# pse84 register map
Vendor: Cypress Semiconductor; Series: PSE84; File version: 1.0
CPU: CM33 r0p1, little endian, MPU, FPU, VTOR, 3 interrupt priority bits
Registers are 32-bit, read-write, reset 0x0 unless marked. A register's access mark holds for its fields unless they carry their own. Offsets are from the block's base; [hi:lo] are bit positions; {n}, {i} and the like mark numbered series; <NAME> marks a mode.

## SCB0 (part 1 of 2) — Serial Communications Block (SPI/UART/I2C)
Base 0x42990000
Same registers: SCB{n} {0x42980000+0x10000*n} (n=2..11), SCB1 0x42D00000
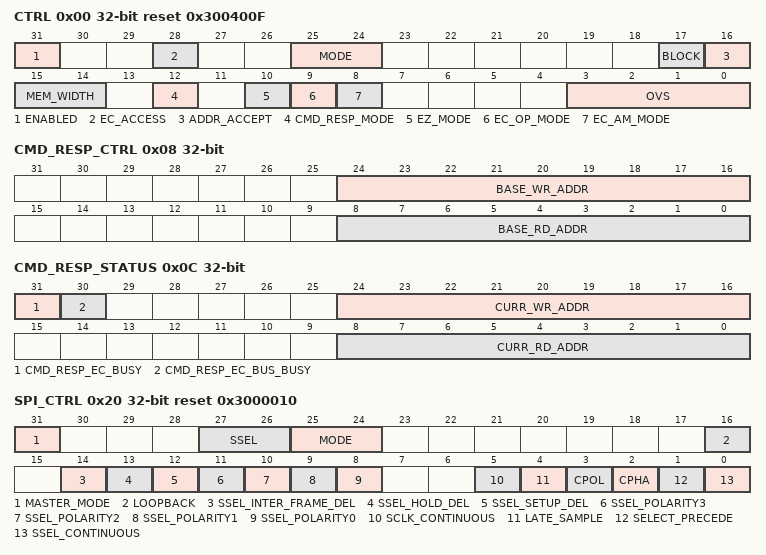
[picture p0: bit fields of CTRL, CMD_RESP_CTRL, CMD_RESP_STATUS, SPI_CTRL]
0x00 CTRL reset 0x300400F — Generic control
  [31] ENABLED — IP enabled ('1') or not ('0'). The proper order in which to initialize the IP is as follows: - Program protocol specific information using SPI_CTRL, UART_CTRL (and UART_TX_CTRL and UART_RX_CTRL) or I2C_CTRL. This includes selection of a submode, master/slave functionality and transmitter/receiver functionality when applicable. - Program generic transmitter (TX_CTRL) and receiver (RX_CTRL) information. This includes enabling of the transmitter and receiver functionality. - Program transmitter FIFO (TX_FIFO_CTRL) and receiver FIFO (RX_FIFO_CTRL) information. - Program CTRL to enable IP, select the specific operation mode and oversampling factor. Generally hen the IP is enabled, no control information should be changed. Changes should be made AFTER disabling the IP, e.g. to modify the operation mode (from I2C to SPI) or to go from externally to internally clocked. The change takes effect after the IP is re-enabled. Note that disabling the IP will cause re-initialization of the design and associated state is lost (e.g. FIFO content). Specific to SPI master case, when SCB is idle, below registers can be changed without disabling SCB block, TX_CTRL TX_FIFO_CTRL RX_CTRL RX_FIFO_CTRL SPI_CTRL.SSEL,
  [28] EC_ACCESS — used to enable I2CS_EC or SPIS_EC access to internal SRAM memory. 0: enable clock_scb_en, has no effect on ec_busy_pp 1: disable clock_scb_en, enable ec_busy_pp (grant I2CS_EC or SPIS_EC access) Before going to deepsleep this field should be set to 1. when waking up from DeepSleep power mode, and PLL is locked (clk_scb is at expected frequency), this filed should be set to 0.
  [25:24] MODE
    0=I2C (Inter-Integrated Circuits (I2C) mode.); 1=SPI (Serial Peripheral Interface (SPI) mode.); 2=UART (Universal Asynchronous Receiver/Transmitter (UART) mode.)
  [17] BLOCK — Only used in externally clocked mode. If the externally clocked logic and the MMIO SW accesses to EZ memory coincide/collide, this bit determines whether a SW access should block and result in bus wait states ('BLOCK is 1') or not (BLOCK is '0'). IF BLOCK is '0' and the accesses collide, MMIO read operations return 0xffff:ffff and MMIO write operations are ignored. Colliding accesses are registered as interrupt causes: field BLOCKED of MMIO registers INTR_TX and INTR_RX.
  [16] ADDR_ACCEPT — Determines whether a received matching address is accepted in the RX FIFO ('1') or not ('0'). In I2C mode, this field is used to allow the slave to put the received slave address or general call address in the RX FIFO. Note that a received matching address is put in the RX FIFO when ADDR_ACCEPT is '1' for both I2C read and write transfers. In multi-processor UART receiver mode, this field is used to allow the receiver to put the received address in the RX FIFO. Note: non-matching addresses are never put in the RX FIFO.
  [15:14] MEM_WIDTH — Determines the number of bits per FIFO data element, depending on physical SRAM cell data width. On M0S8/MXS40S platform, the SRAM data width is 16 bit, so WORD (2) is not supported. On MXS40E platform, the SRAM data width is 32 bits.
    0=BYTE (8-bit FIFO data elements. This mode provides the biggest amount of FIFO entries, but TX_CTRL.DATA_WIDTH and RX_CTRL.DATA_WIDTH are restricted to [0, 7].); 1=HALFWORD (16-bit FIFO data elements. TX_CTRL.DATA_WIDTH and RX_CTRL.DATA_WIDTH are restricted to [0, 15].); 2=WORD (32-bit FIFO data elements. This mode provides the smallest amount of FIFO entries, but TX_CTRL.DATA_WIDTH and RX_CTRL.DATA_WIDTH can be in a range of [0, 31].); 3=RSVD (N/A)
  [12] CMD_RESP_MODE — Determines CMD_RESP mode of operation: '0': CMD_RESP mode disabled. '1': CMD_RESP mode enabled (also requires EC_AM_MODE and EC_OP_MODE to be set to '1').
  [10] EZ_MODE — Non EZ mode ('0') or EZ mode ('1'). In EZ mode, a meta protocol is applied to the serial interface protocol. This meta protocol adds meaning to the data frames transferred by the serial interface protocol: a data frame can represent a memory address, a write memory data element or a read memory data element. EZ mode is only used for synchronous serial interface protocols: SPI and I2C. In SPI mode, only Motorola submode (all Motorola modes: 0, 1, 2, 3) is supported and the transmitter should use continuous data frames; i.e. data frames mot separated by slave deselection. This mode is only applicable to slave functionality. In EZ mode, the slave can read from and write to an addressable memory structure of up to 256 bytes. In EZ mode, data frames should 8-bit in size and should be transmitted and received with the Most Significant Bit (MSB) first. In UART mode this field should be '0'.
  [9] EC_OP_MODE — Internally clocked mode ('0') or externally clocked mode ('1') operation. In internally clocked mode, the serial interface protocols run off the peripheral clock. In externally clocked mode, the serial interface protocols run off the clock as provided by the serial interface. Externally clocked operation mode is only used for synchronous serial interface protocols (SPI and I2C) in slave mode AND EZ mode. In SPI mode, only Motorola submode (all Motorola modes: 0, 1, 2, 3) is supported. The maximum SPI slave, EZ mode bitrate is 48 Mbps (transmission and IO delays outside the IP will degrade the effective bitrate). In UART mode this field should be '0'.
  [8] EC_AM_MODE — Internally clocked mode ('0') or externally clocked mode ('1') address matching (I2C) or selection (SPI). In internally clocked mode, the serial interface protocols run off the peripheral clock. In externally clocked mode, the serial interface protocols run off the clock as provided by the serial interface. Externally clocked mode is only used for synchronous serial interface protocols (SPI and I2C) in slave mode. In SPI mode, only Motorola submode (all Motorola modes: 0, 1, 2, 3) is supported. In UART mode this field should be '0'.
  [3:0] OVS
0x04 STATUS ro reset not defined — Generic status
  [0] EC_BUSY — Indicates whether the externally clocked logic is potentially accessing the EZ memory (this is only possible in EZ mode). This bit can be used by SW to determine whether it is safe to issue a SW access to the EZ memory (without bus wait states (a blocked SW access) or bus errors being generated). Note that the INTR_TX.BLOCKED and INTR_RX.BLOCKED interrupt causes are used to indicate whether a SW access was actually blocked by externally clocked logic.
0x08 CMD_RESP_CTRL — Command/response control
  [24:16] BASE_WR_ADDR — I2C/SPI write base address for CMD_RESP mode. Address is used by a I2C CMD_RESP mode write transfer (CTRL.MODE is I2C) or a SPI CMD_RESP mode write transfer (CTRL.MODE is SPI): at the start of a write transfer BASE_WR_ADDR is copied to CMD_RESP_STATUS.CURR_WR_ADDR. This field should not be modified during ongoing bus transfers.
  [8:0] BASE_RD_ADDR — I2C/SPI read base address for CMD_RESP mode. Address is used by a I2C CMD_RESP mode read transfer (CTRL.MODE is I2C) or a SPI CMD_RESP mode read transfer (CTRL.MODE is SPI): at the start of a read transfer BASE_RD_ADDR is copied to CMD_RESP_STATUS.CURR_RD_ADDR. This field should not be modified during ongoing bus transfers.
0x0C CMD_RESP_STATUS ro reset not defined — Command/response status
  [31] CMD_RESP_EC_BUSY — Indicates whether the CURR_RD_ADDR and CURR_WR_ADDR fields in this register are reliable (when CMD_RESP_EC_BUSY is '0') or not reliable (when CMD_RESP_EC_BUSY is '1'). Note: - When there is no ongoing bus transfer, CMD_RESP_EC_BUSY is '0' (reliable). - When there is a ongoing bus transfer, CMD_RESP_EC_BUSY is '0' (reliable), when the CURR_RD_ADDR and CURR_WR_ADDR are not being updated by the HW. - When there is a ongoing bus transfer, CMD_RESP_EC_BUSY is '1' (not reliable), when the CURR_RD_ADDR or CURR_WR_ADDR are being updated by the HW. Note that this update lasts one I2C clock cycle, or two SPI clock cycles.
  [30] CMD_RESP_EC_BUS_BUSY — Indicates whether there is an ongoing bus transfer to the IP. '0': no ongoing bus transfer. '1': ongoing bus transfer. For SPI, the field is '1' when the slave is selected. For I2C, the field is set to '1' at a I2C START/RESTART. In case of an address match, the field is set to '0' on a I2C STOP. In case of NO address match, the field is set to '0' after the failing address match.
  [24:16] CURR_WR_ADDR — I2C/SPI write current address for CMD_RESP mode. HW increments the field after a read access to the memory buffer. However, when the last memory buffer address is reached, the address is NOT incremented (but remains at the maximum memory buffer address). The field is used to determine how many bytes have been written (# bytes = CURR_WR_ADDR - CMD_RESP_CTRL.BASE_WR_ADDR). This field is reliable during when there is no bus transfer. This field is potentially unreliable when there is a bus transfer bus transfer: when CMD_RESP_EC_BUSY is '0', the field is reliable.
  [8:0] CURR_RD_ADDR — I2C/SPI read current address for CMD_RESP mode. HW increments the field after a read access to the memory buffer. However, when the last memory buffer address is reached, the address is NOT incremented (but remains at the maximum memory buffer address). The field is used to determine how many bytes have been read (# bytes = CURR_RD_ADDR - CMD_RESP_CTRL.BASE_RD_ADDR). This field is reliable during when there is no bus transfer. This field is potentially unreliable when there is a bus transfer bus transfer: when CMD_RESP_EC_BUSY is '0', the field is reliable.
0x20 SPI_CTRL reset 0x3000010 — SPI control
  [31] MASTER_MODE — Master ('1') or slave ('0') mode. In master mode, transmission will commence on availability of data frames in the TX FIFO. In slave mode, when selected and there is no data frame in the TX FIFO, the slave will transmit all '1's. In both master and slave modes, received data frames will be lost if the RX FIFO is full.
  [27:26] SSEL — Selects one of the four incoming/outgoing SPI slave select signals: - 0: Slave 0, SSEL[0]. - 1: Slave 1, SSEL[1]. - 2: Slave 2, SSEL[2]. - 3: Slave 3, SSEL[3]. The IP should be disabled when changes are made to this field.
  [25:24] MODE
    0=SPI_MOTOROLA (SPI Motorola submode. In master mode, when not transmitting data (SELECT is inactive), SCLK is stable at CPOL. In slave mode, when not selected, SCLK is ignored; i.e. it can be either stable or clocking. In master mode, when there is no data to transmit (TX FIFO is empty), SELECT is inactive.); 1=SPI_TI (SPI Texas Instruments submode. In master mode, when not transmitting data, SCLK is stable at '0'. In slave mode, when not selected, SCLK is ignored; i.e. it can be either stable or clocking. In master mode, when there is no data to transmit (TX FIFO is empty), SELECT is inactive; i.e. no pulse is generated.); 2=SPI_NS (SPI National Semiconductors submode. In master mode, when not transmitting data, SCLK is stable at '0'. In slave mode, when not selected, SCLK is ignored; i.e. it can be either stable or clocking. In master mode, when there is no data to transmit (TX FIFO is empty), SELECT is inactive.)
  [16] LOOPBACK — Local loopback control (does NOT affect the information on the pins). Only used in master mode. Not used in National Semiconductors submode. '0': the SPI master MISO line 'spi_miso_in' is connected to the SPI MISO pin. '1': the SPI master MISO line 'spi_miso_in' is connected to the SPI master MOSI line 'spi_mosi_out'. In other words, in loopback mode the SPI master receives on MISO what it transmits on MOSI.
  [14] SSEL_INTER_FRAME_DEL — Indicates the SPI SELECT inter-dataframe delay (between SELECT deactivation and SELECT activation). '0': 1.5 SPI clock cycles '1': 2.5 SPI clock cycles Only applies in SPI MOTOROLA submode and when SPI_CTRL.SSEL_CONTINUOUS=0, CTRL.OVS>=3. above are ideal case at SCB block level, and there is inaccuracy of one clk_scb cycle.
  [13] SSEL_HOLD_DEL — Indicates the SPI SELECT hold delay (between SPI clock edge to sample the last MOSI bit, and SELECT deactivation). '0': 0.75 SPI clock cycles '1': 1.75 SPI clock cycles Only applies in SPI MOTOROLA submode and when SCLK_CONTINUOUS=0, CTRL.OVS>=3. above are ideal case at SCB block level, and there is inaccuracy of one clk_scb cycle.
  [12] SSEL_SETUP_DEL — Indicates the SPI SELECT setup delay (between SELECT activation and SCLK clock edge to sample the first MOSI bit). '0': 0.75 SPI clock cycles '1': 1.75 SPI clock cycles Only applies in SPI MOTOROLA submode and when SCLK_CONTINUOUS=0, CTRL.OVS>=3. above are ideal case at SCB block level, and there is inaccuracy of one clk_scb cycle.
  [11] SSEL_POLARITY3 — Slave select polarity.
  [10] SSEL_POLARITY2 — Slave select polarity.
  [9] SSEL_POLARITY1 — Slave select polarity.
  [8] SSEL_POLARITY0 — Slave select polarity. SSEL_POLARITY0 applies to the outgoing SPI slave select signal 0 (master mode) and to the incoming SPI slave select signal (slave mode). For Motorola and National Semiconductors submodes: '0': slave select is low/'0' active. '1': slave select is high/'1' active. For Texas Instruments submode: '0': high/'1' active precede/coincide pulse. '1': low/'0' active precede/coincide pulse.
  [5] SCLK_CONTINUOUS — Only applicable in master mode. '0': SCLK is generated, when the SPI master is enabled and data is transmitted. '1': SCLK is generated, when the SPI master is enabled. This mode is useful for slave devices that use SCLK for functional operation other than just SPI functionality.
  [4] LATE_SAMPLE — Changes the SCLK edge on which MISO is captured in master mode, or MOSI is captured in slave mode. When '0', the default applies, for Motorola as determined by CPOL and CPHA, for Texas Instruments on the falling edge of SCLK(CPOL is '0' and CPHA is '1'), for National Semiconductors on the rising edge of SCLK(CPOL is '0' and CPHA is '0'). When '1', the alternate clock edge is used (which comes half a SPI SCLK period later). for master, applicable to all Motorola, TI and National Semiconductors flavors, and CPOL/CPHA timing mdoes. for slave, applicable to Motorola flavor only, and CPHA=0 timing modes only, and internally-clocked mode only. Late sampling addresses the round trip delay associated with transmitting SCLK from the master to the slave and transmitting MISO from the slave to the master.
  [3] CPOL — Indicates the clock polarity. This field, together with the CPHA field, indicates when MOSI data is driven and MISO data is captured: - CPOL is '0': SCLK is '0' when not transmitting data. - CPOL is '1': SCLK is '1' when not transmitting data.
  [2] CPHA — Indicates the clock phase. This field, together with the CPOL field, indicates when MOSI data is driven and MISO data is captured: - Motorola mode 0. CPOL is '0', CPHA is '0': MOSI is driven on a falling edge of SCLK. MISO is captured on a rising edge of SCLK. - Motorola mode 1. CPOL is '0', CPHA is '1': MOSI is driven on a rising edge of SCLK. MISO is captured on a falling edge of SCLK. - Motorola mode 2. CPOL is '1', CPHA is '0': MOSI is driven on a rising edge of SCLK. MISO is captured on a falling edge of SCLK. - Motorola mode 3. CPOL is '1', CPHA is '1': MOSI is driven on a falling edge of SCLK. MISO is captured on a rising edge of SCLK. In SPI Motorola submode, all four CPOL/CPHA modes are valid. in SPI NS submode, only CPOL=0 CPHA=0 mode is valid. in SPI TI submode, only CPOL=0 CPHA=1 mode is valid.
  [1] SELECT_PRECEDE — Only used in SPI Texas Instruments' submode. When '1', the data frame start indication is a pulse on the SELECT line that precedes the transfer of the first data frame bit. When '0', the data frame start indication is a pulse on the SELECT line that coincides with the transfer of the first data frame bit.
  [0] SSEL_CONTINUOUS — Continuous SPI data transfers enabled ('1') or not ('0'). This field is used in master mode. In slave mode, both continuous and non-continuous SPI data transfers are supported independent of this field. When continuous transfers are enabled individual data frame transfers are not necessarily separated by slave deselection (as indicated by the level or pulse on the SELECT line): if the TX FIFO has multiple data frames, data frames are send out without slave deselection. When continuous transfers are not enabled individual data frame transfers are always separated by slave deselection: data frames are always separated by slave deselection.
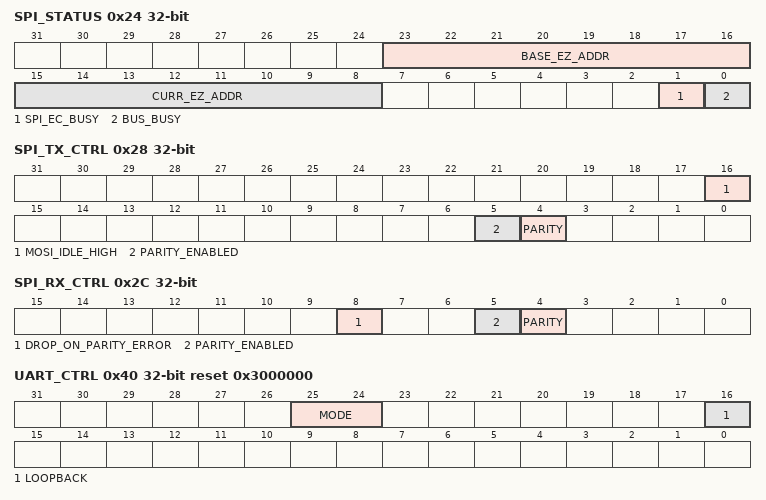
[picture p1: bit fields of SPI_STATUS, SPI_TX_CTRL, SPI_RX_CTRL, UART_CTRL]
0x24 SPI_STATUS ro reset not defined
  [23:16] BASE_EZ_ADDR — SPI base EZ address. Address as provided by a SPI write transfer. This field is only reliable in internally clocked mode. In externally clocked mode the field may be unreliable, as clock domain synchronization is not performed in the design.
  [15:8] CURR_EZ_ADDR — SPI current EZ address. Current address pointer. This field is only reliable in internally clocked mode. In externally clocked mode the field may be unreliable (during an ongoing transfer when SPI_EC_BUSY is '1'), as clock domain synchronization is not performed in the design.
  [1] SPI_EC_BUSY — Indicates whether the externally clocked logic is potentially accessing the EZ memory and/or updating BASE_ADDR or CURR_ADDR (this is only possible in EZ mode). This bit can be used by SW to determine whether BASE_ADDR and CURR_ADDR are reliable.
  [0] BUS_BUSY — SPI bus is busy. The bus is considered busy ('1') during an ongoing transaction. For Motorola and National submodes, the busy bit is '1', when the slave selection is activated. For TI submode, the busy bit is '1' from the time the preceding/coinciding slave select is activated for the first transmitted data frame, till the last MOSI/MISO bit of the last data frame is transmitted.
0x28 SPI_TX_CTRL — SPI transmitter control
  [16] MOSI_IDLE_HIGH — SPI master MOSI output level when SELECT output inactive, 0: retain the level of last data bit 1: change to high, (MOSI level is high, before the first data bit time, and after data bit time, defined SSEL/SCLK driving edge with CPOL/CPHA)
  [5] PARITY_ENABLED — Parity generation enabled ('1') or not ('0').
  [4] PARITY — Parity bit. When '0', the transmitter generates an even parity. When '1', the transmitter generates an odd parity.
0x2C SPI_RX_CTRL — SPI receiver control
  [8] DROP_ON_PARITY_ERROR — Behavior when a parity check fails. When '0', received data is send to the RX FIFO. When '1', received data is dropped and lost.
  [5] PARITY_ENABLED — Parity checking enabled ('1') or not ('0').
  [4] PARITY — Parity bit. When '0', the receiver expects an even parity. When '1', the receiver expects an odd parity.
0x40 UART_CTRL reset 0x3000000 — UART control
  [25:24] MODE
    0=UART_STD (Standard UART submode.); 1=UART_SMARTCARD (SmartCard (ISO7816) submode. Support for negative acknowledgement (NACK) on the receiver side and retransmission on the transmitter side.); 2=UART_IRDA (Infrared Data Association (IrDA) submode. Return to Zero modulation scheme.)
  [16] LOOPBACK — Local loopback control (does NOT affect the information on the pins). When '0', the transmitter TX line 'uart_tx_out' is connected to the TX pin and the receiver RX line 'uart_rx_in' is connected to the RX pin. When '1', the transmitter TX line 'uart_tx_out' is connected to the receiver RX line 'uart_rx_in'. A similar connections scheme is followed for 'uart_rts_out' and 'uart_cts_in'. This allows a SCB UART transmitter to communicate with its receiver counterpart.
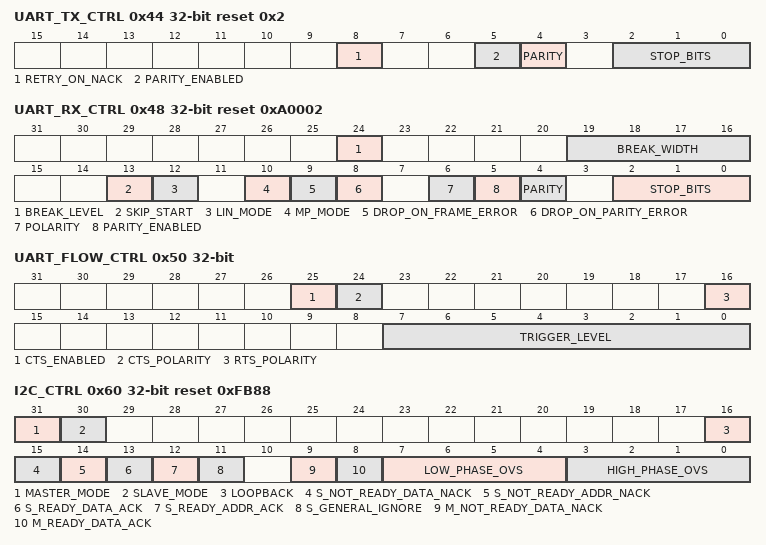
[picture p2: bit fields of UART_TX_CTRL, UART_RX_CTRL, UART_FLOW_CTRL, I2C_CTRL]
0x44 UART_TX_CTRL reset 0x2 — UART transmitter control
  [8] RETRY_ON_NACK — When '1', a data frame is retransmitted when a negative acknowledgement is received. Only applicable to the SmartCard submode.
  [5] PARITY_ENABLED — Parity generation enabled ('1') or not ('0'). Only applicable in standard UART submodes. In SmartCard submode, parity generation is always enabled through hardware. In IrDA submode, parity generation is always disabled through hardware
  [4] PARITY — Parity bit. When '0', the transmitter generates an even parity. When '1', the transmitter generates an odd parity. Only applicable in standard UART and SmartCard submodes.
  [2:0] STOP_BITS — Stop bits. STOP_BITS + 1 is the duration of the stop period in terms of halve bit periods. Valid range is [1, 7]; i.e. a stop period should last at least one bit period.
0x48 UART_RX_CTRL reset 0xA0002 — UART receiver control
  [24] BREAK_LEVEL — 0: low level pulse detection, like Break field in LIN protocol 1: high level pulse detection, like IFS field in CXPI protocol, or idle line state in UART
  [19:16] BREAK_WIDTH — Break width. BREAK_WIDTH + 1 is the minimum width in bit periods of a break. During a break the transmitted/received line value is '0'. This feature is useful for standard UART submode and LIN submode ('break field' detection). Once, the break is detected, the INTR_RX.BREAK_DETECT bit is set to '1'. Note that break detection precedes baud rate detection, which is used to synchronize/refine the receiver clock to the transmitter clock. As a result, break detection operates with an unsynchronized/unrefined receiver clock. Therefore, the receiver's definition of a bit period is imprecise and the setting of this field should take this imprecision into account. The LIN standard also accounts for this imprecision: a LIN start bit followed by 8 data bits allows for up to 9 consecutive '0' bit periods during regular transmission, whereas the LIN break detection should be at least 13 consecutive '0' bit periods. This provides for a margin of 4 bit periods. Therefore, the default value of this field is set to 10, representing a minimal break field with of 10+1 = 11 bit periods; a value in between the 9 consecutive bit periods of a regular transmission and the 13 consecutive bit periods of a break field. This provides for slight imprecisions of the receiver clock wrt. the transmitter clock. There should not be a need to program this field to any value other than its default value.
  [13] SKIP_START — Only applicable in standard UART submode. When '1', the receiver skips start bit detection for the first received data frame. Instead, it synchronizes on the first received data frame bit, which should be a '1'. This functionality is intended for wake up from DeepSleep when receiving a data frame. The transition from idle ('1') to START ('0') on the RX line is used to wake up the CPU. The transition detection (and the associated wake up functionality) is performed by the GPIO2 IP. The woken up CPU will enable the SCB's UART receiver functionality. Once enabled, it is assumed that the START bit is ongoing (the CPU wakeup and SCB enable time should be less than the START bit period). The SCB will synchronize to a '0' to '1' transition, which indicates the first data frame bit is received (first data frame bit should be '1'). After synchronization to the first data frame bit, the SCB will resume normal UART functionality: subsequent data frames will be synchronized on the receipt of a START bit.
  [12] LIN_MODE — Only applicable in standard UART submode. When '1', the receiver performs break detection and baud rate detection on the incoming data. First, break detection counts the amount of bit periods that have a line value of '0'. BREAK_WIDTH specifies the minimum required amount of bit periods. Successful break detection sets the INTR_RX.BREAK_DETECT interrupt cause to '1'. Second, baud rate detection counts the amount of peripheral clock periods that are use to receive the synchronization byte (0x55; least significant bit first). The count is available through UART_RX_STATUS.BR_COUNTER. Successful baud rate detection sets the INTR_RX.BAUD_DETECT interrupt cause to '1' (BR_COUNTER is reliable). This functionality is used to synchronize/refine the receiver clock to the transmitter clock. The receiver software can use the BR_COUNTER value to set the right IP clock (from the programmable clock IP) to guarantee successful receipt of the first LIN data frame (Protected Identifier Field) after the synchronization byte.
  [10] MP_MODE — Multi-processor mode. When '1', multi-processor mode is enabled. In this mode, RX_CTRL.DATA_WIDTH should indicate a 9-bit data frame. In multi-processor mode, the 9th received bit of a data frame separates addresses (bit is '1') from data (bit is '0'). A received address is matched with RX_MATCH.DATA and RX_MATCH.MASK. In the case of a match, subsequent received data are sent to the RX FIFO. In the case of NO match, subsequent received data are dropped.
  [9] DROP_ON_FRAME_ERROR — Behavior when an error is detected in a start or stop period. When '0', received data is send to the RX FIFO. When '1', received data is dropped and lost.
  [8] DROP_ON_PARITY_ERROR — Behavior when a parity check fails. When '0', received data is send to the RX FIFO. When '1', received data is dropped and lost. Only applicable in standard UART and SmartCard submodes (negatively acknowledged SmartCard data frames may be dropped with this field).
  [6] POLARITY — Inverts incoming RX line signal 'uart_rx_in'. Inversion is after local loopback. This functionality is intended for IrDA receiver functionality.
  [5] PARITY_ENABLED — Parity checking enabled ('1') or not ('0'). Only applicable in standard UART submode. In SmartCard submode, parity checking is always enabled through hardware. In IrDA submode, parity checking is always disabled through hardware.
  [4] PARITY — Parity bit. When '0', the receiver expects an even parity. When '1', the receiver expects an odd parity. Only applicable in standard UART and SmartCard submodes.
  [2:0] STOP_BITS — Stop bits. STOP_BITS + 1 is the duration of the stop period in terms of halve bit periods. Valid range is [1, 7]; i.e. a stop period should last at least one bit period. Note that in case of a stop bits error, the successive data frames may get lost as the receiver needs to resynchronize its start bit detection. The amount of lost data frames depends on both the amount of stop bits, the idle ('1') time between data frames and the data frame value.
0x4C UART_RX_STATUS ro reset not defined — UART receiver status
  [11:0] BR_COUNTER — Amount of peripheral clock periods that constitute the transmission of a 0x55 data frame (sent least significant bit first) as determined by the receiver. BR_COUNTER / 8 is the amount of peripheral clock periods that constitute a bit period. This field has valid data when INTR_RX.BAUD_DETECT is set to '1'.
0x50 UART_FLOW_CTRL — UART flow control
  [25] CTS_ENABLED — Enable use of CTS input signal 'uart_cts_in' by the UART transmitter: '0': Disabled. The UART transmitter ignores 'uart_cts_in', and transmits when a data frame is available for transmission in the TX FIFO or the TX shift register. '1': Enabled. The UART transmitter uses 'uart_cts_in' to qualify the transmission of data. It transmits when 'uart_cts_in' is active and a data frame is available for transmission in the TX FIFO or the TX shift register. If UART_CTRL.LOOPBACK is '1', 'uart_cts_in' is connected to 'uart_rts_out' in the IP (both signals are subjected to signal polarity changes as indicated by RTS_POLARITY and CTS_POLARITY).
  [24] CTS_POLARITY — Polarity of the CTS input signal 'uart_cts_in': '0': CTS is low/'0' active; 'uart_cts_in' is '0' when active and 'uart_cts_in' is '1' when inactive. '1': CTS is high/'1' active; 'uart_cts_in' is '1' when active and 'uart_cts_in' is '0' when inactive.
  [16] RTS_POLARITY — Polarity of the RTS output signal 'uart_rts_out': '0': RTS is low/'0' active; 'uart_rts_out' is '0' when active and 'uart_rts_out' is '1' when inactive. '1': RTS is high/'1' active; 'uart_rts_out' is '1' when active and 'uart_rts_out' is '0' when inactive. During IP reset (Hibernate system power mode), 'uart_rts_out' is '1'. This represents an inactive state assuming a low/'0' active polarity.
  [7:0] TRIGGER_LEVEL — Trigger level. When the receiver FIFO has less entries than the amount of this field, a Ready To Send (RTS) output signal 'uart_rts_out' is activated. By setting this field to '0', flow control is effectively SW disabled (may be useful for debug purposes).
0x60 I2C_CTRL reset 0xFB88 — I2C control
  [31] MASTER_MODE — Master mode enabled ('1') or not ('0'). Note that both master and slave modes can be enabled at the same time. This allows the IP to address itself.
  [30] SLAVE_MODE — Slave mode enabled ('1') or not ('0').
  [16] LOOPBACK — Local loopback control (does NOT affect the information on the pins). Only applicable in master/slave mode. When '0', the I2C SCL and SDA lines are connected to the I2C SCL and SDA pins. When '1', I2C SCL and SDA lines are routed internally in the peripheral, and as a result unaffected by other I2C devices. This allows a SCB I2C peripheral to address itself.
  [15] S_NOT_READY_DATA_NACK — For internally clocked logic only. Only used when: - non EZ mode. Functionality is as follows: - 1: a received data element byte the slave is immediately NACK'd when the receiver FIFO is full. - 0: clock stretching is performed (till the receiver FIFO is no longer full).
  [14] S_NOT_READY_ADDR_NACK — For internally clocked logic (EC_AM is '0' and EC_OP is '0') on an address match or general call address (and S_GENERAL_IGNORE is '0'). Only used when: - EC_AM is '0', EC_OP is '0' and non EZ mode. Functionality is as follows: - 1: a received (matching) slave address is immediately NACK'd when the receiver FIFO is full. - 0: clock stretching is performed (till the receiver FIFO is no longer full). For externally clocked logic (EC_AM is '1') on an address match or general call address (and S_GENERAL_IGNORE is '0'). Only used when (NOT used when EC_AM is '1' and EC_OP is '1' and address match and EZ mode): - EC_AM is '1' and EC_OP is '0'. - EC_AM is '1' and general call address match. - EC_AM is '1' and non EZ mode. Functionality is as follows: - 1: a received (matching or general) slave address is always immediately NACK'd. There are two possibilities: 1). the internally clocked logic is enabled (we are in Active system power mode) and it handles the rest of the current transfer. In this case the I2C master will not observe the NACK. 2). the internally clocked logic is not enabled (we are in DeepSleep system power mode). In this case the I2C master will observe the NACK and may retry the transfer in the future (which gives the internally clocked logic the time to wake up from DeepSleep system power mode). - 0: clock stretching is performed (till the internally clocked logic takes over). The internally clocked logic will handle the ongoing transfer as soon as it is enabled.
  [13] S_READY_DATA_ACK — When '1', a received data element by the slave is immediately ACK'd when the receiver FIFO is not full. In EZ mode, this field should be set to '1'.
  [12] S_READY_ADDR_ACK — When '1', a received (matching) slave address is immediately ACK'd when the receiver FIFO is not full. In EZ mode, this field should be set to '1'.
  [11] S_GENERAL_IGNORE — When '1', a received general call slave address is immediately NACK'd (no ACK or clock stretching) and treated as a non matching slave address. This is useful for slaves that do not need any data supplied within the general call structure.
  [9] M_NOT_READY_DATA_NACK — for I2C master, the NACKed byte should be properly received. it write the data byte, before ACK/NACK decision. When '1', if a received data element byte is written, and the receiver FIFO become full, the master send out NACK . if the reciever FIFO is full (the received data byte cannot be written), it stretch SCL(extend SCL low phase) until the receiver FIFO changes to not full, to write the last byte, then send out NACK. When '0', clock stretching is used instead (till the receiver FIFO is no longer full).
  [8] M_READY_DATA_ACK — When '1', a received data element by the master is immediately ACK'd when the receiver FIFO is not full.
  [7:4] LOW_PHASE_OVS — Serial I2C interface low phase oversampling factor. LOW_PHASE_OVS + 1 peripheral clock periods constitute the low phase of a bit period. The valid range is [7, 15] with input signal median filtering and [6, 15] without input signal median filtering. The field is mainly used in master mode. In slave mode, there is a frequency requirement for the IP clock wrt. the regular (no stretching) interface (IF) low time to guarantee functional correct behavior. With input signal median filtering, the IF low time should be >= 8 IP clock cycles and <= 16 IP clock cycles. Without input signal median filtering, the IF low time should be >= 7 IP clock cycles and <= 16 IP clock cycles. in slave mode, this field is used to define number of clk_scb cycles for tSU-DAT timing (from ACK/NACK/data ready, to SCL rising edge (released from I2C slave clock stretching))
  [3:0] HIGH_PHASE_OVS — Serial I2C interface high phase oversampling factor. HIGH_PHASE_OVS + 1 peripheral clock periods constitute the high phase of a bit period. The valid range is [5, 15] with input signal median filtering and [4, 15] without input signal median filtering. The field is only used in master mode. In slave mode, the field is NOT used. However, there is a frequency requirement for the IP clock wrt. the regular interface (IF) high time to guarantee functional correct behavior. With input signal median filtering, the IF high time should be >= 6 IP clock cycles and <= 16 IP clock cycles. Without input signal median filtering, the IF high time should be >= 5 IP clock cycles and <= 16 IP clock cycles.
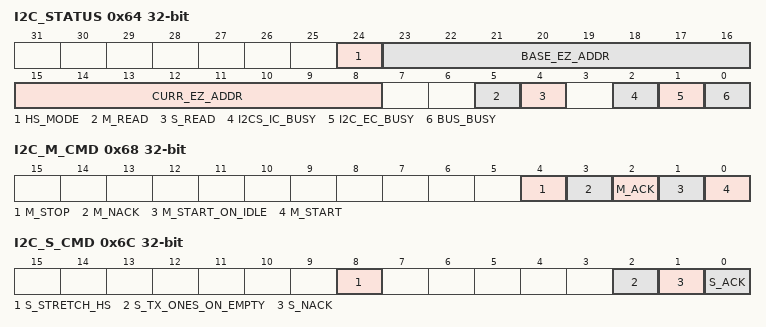
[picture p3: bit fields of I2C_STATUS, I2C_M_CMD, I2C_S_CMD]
0x64 I2C_STATUS ro (reset mask 0x1000035)
  [24] HS_MODE — this is to indicate I2C Hs-mode transfer, it is set, after 'Start, master-code, NACK'' pattern, for I2CM, at SCL falling edge, (INTR_M.I2C_HS_ENTER triggers), for I2CS_IC, at SCL falling edge, (INTR_S.I2C_HS_ENTER triggers), for I2CS_EC, at SCL rising edge, after 2-DFF synchronization delay, when CTRL.EC_AM =1, AND CTRL.EC_ACCESS =0, it is cleared when Stop pattern is detected, for I2CM, INTR_M.I2C_HS_EXIT triggers, for I2CS_IC, INTR_S.I2C_HS_EXIT triggers, for I2CS_EC, there is no respective interrupt.
  [23:16] BASE_EZ_ADDR — I2C slave base EZ address. Address as provided by an I2C write transfer. This field is only reliable in internally clocked mode. In externally clocked mode the field may be unreliable, as clock domain synchronization is not performed in the design.
  [15:8] CURR_EZ_ADDR — I2C slave current EZ address. Current address pointer. This field is only reliable in internally clocked mode. In externally clocked mode the field may be unreliable (during an ongoing transfer when I2C_EC_BUSY is '1'), as clock domain synchronization is not performed in the design.
  [5] M_READ — I2C master read transfer ('1') or I2C master write transfer ('0'). When the I2C master is inactive/idle or transmitting START, REPEATED START, STOP or an address, this field is '0''.
  [4] S_READ — I2C slave read transfer ('1') or I2C slave write transfer ('0'). When the I2C slave is inactive/idle or receiving START, REPEATED START, STOP or an address, this field is '0''.
  [2] I2CS_IC_BUSY — Indicates whether the internally clocked slave logic is being accessed by external I2C master. --set at ADDR_MATCH --clear at START/RESET, STOP detection, or BUS_ERROR This bit can be used by SW to determine whether I2CS_IC is busy before entering DeepSleep.
  [1] I2C_EC_BUSY — Indicates whether the externally clocked logic is potentially accessing the EZ memory and/or updating BASE_EZ_ADDR or CURR_EZ_ADDR (this is only possible in EZ mode). This bit can be used by SW to determine whether BASE_EZ_ADDR and CURR_EZ_ADDR are reliable.
  [0] BUS_BUSY — I2C bus is busy. The bus is considered busy ('1'), from the time a START is detected or from the time the SCL line is '0'. The bus is considered idle ('0'), from the time a STOP is detected. If the IP is disabled, BUS_BUSY is '0'. After enabling the IP, it takes time for the BUS_BUSY to detect a busy bus. This time is the maximum high time of the SCL line. For a 100 kHz interface frequency, this maximum high time may last roughly 5 us (half a bit period). For single master systems, BUS_BUSY does not have to be used to detect an idle bus before a master starts a transfer using I2C_M_CMD.M_START (no bus collisions). For multi-master systems, BUS_BUSY can be used to detect an idle bus before a master starts a transfer using I2C_M_CMD.M_START_ON_IDLE (to prevent bus collisions).
0x68 I2C_M_CMD — I2C master command
  [4] M_STOP — When '1', attempt to transmit a STOP. When this action is performed, the hardware sets this field to '0'. I2C_M_CMD.M_START has a higher priority than this command: in situations where both a STOP and a REPEATED START could be transmitted, M_START takes precedence over M_STOP.
  [3] M_NACK — for I2C master, the NACKed byte should be properly received. it write the data byte, before ACK/NACK decision. When '1', attempt to transmit a negative acknowledgement (NACK). if the reciever FIFO is full (the received data byte cannot be written), it stretch SCL(extend SCL low phase) until the receiver FIFO changes to not full, to write the last byte, then send out NACK. When this action is performed, the hardware sets this field to '0'.
  [2] M_ACK — When '1', attempt to transmit an acknowledgement (ACK). When this action is performed, the hardware sets this field to '0'.
  [1] M_START_ON_IDLE — When '1', transmit a START as soon as the bus is idle (I2C_STATUS.BUS_BUSY is '0', note that BUSY has a default value of '0'). For bus idle detection the hardware relies on STOP detection. As a result, bus idle detection is only functional after at least one I2C bus transfer has been detected on the bus (default/reset value of BUSY is '0') . A START is only transmitted when the master state machine is in the default state. When this action is performed, the hardware sets this field to '0'.
  [0] M_START — When '1', transmit a START or REPEATED START. Whether a START or REPEATED START is transmitted depends on the state of the master state machine. A START is only transmitted when the master state machine is in the default state. A REPEATED START is transmitted when the master state machine is not in the default state, but is working on an ongoing transaction. The REPEATED START can only be transmitted after a NACK or ACK has been received for a transmitted data element or after a NACK has been transmitted for a received data element. When this action is performed, the hardware sets this field to '0'.
0x6C I2C_S_CMD — I2C slave command
  [8] S_STRETCH_HS — When '1', attempt to stretch SCL at time t1, SCL falling edge after 'START, Master-code, NACK' pattern is detected. When I2C_CTRL.HS_ENABLED is set, it should be set; after wakeup from DeepSleep power mode, it should also be set. When INTR_S.I2C_HS_ENTER triggers, firmware configure clk_scb to meet I2C Hs-mode timing requirements, then firmware can clear this bit.
  [2] S_TX_ONES_ON_EMPTY — When '1', attempt to send ones when TX_FIFO is empty. Once hardware starts to send ones, it will continue send ones until NACK is received, regardless of TX_FIFO status (even if new data is written into TX_FIFO). This bit is used to avoid stretching SCL, which is not expected for some master devices.
  [1] S_NACK — When '1', attempt to transmit a negative acknowledgement (NACK). When this action is performed, the hardware sets this field to '0'. In EZ mode, this field should be set to '0' (it is only to be used in non EZ mode). This command has a higher priority than I2C_S_CMD.S_ACK, I2C_CTRL.S_READY_ADDR_ACK or I2C_CTRL.S_READY_DATA_ACK.
  [0] S_ACK — When '1', attempt to transmit an acknowledgement (ACK). When this action is performed, the hardware sets this field to '0'. In EZ mode, this field should be set to '0' (it is only to be used in non EZ mode).
